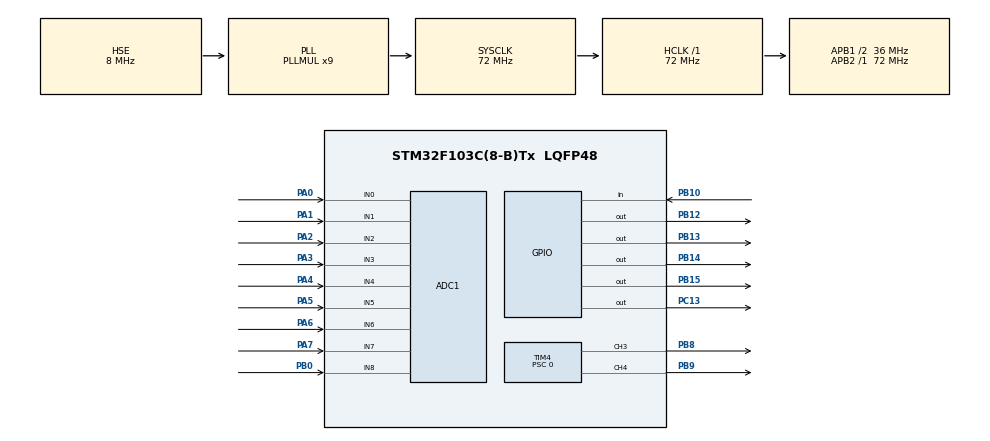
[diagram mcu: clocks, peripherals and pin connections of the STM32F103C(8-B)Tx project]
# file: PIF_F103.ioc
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ADC1.Channel-0\#ChannelRegularConversion=ADC_CHANNEL_0
ADC1.Channel-1\#ChannelRegularConversion=ADC_CHANNEL_1
ADC1.Channel-2\#ChannelRegularConversion=ADC_CHANNEL_2
ADC1.Channel-3\#ChannelRegularConversion=ADC_CHANNEL_3
ADC1.Channel-4\#ChannelRegularConversion=ADC_CHANNEL_4
ADC1.Channel-5\#ChannelRegularConversion=ADC_CHANNEL_5
ADC1.Channel-6\#ChannelRegularConversion=ADC_CHANNEL_6
ADC1.Channel-7\#ChannelRegularConversion=ADC_CHANNEL_7
ADC1.Channel-8\#ChannelRegularConversion=ADC_CHANNEL_8
ADC1.ContinuousConvMode=DISABLE
ADC1.ExternalTrigConv=ADC_EXTERNALTRIGCONV_T3_TRGO
ADC1.NbrOfConversion=9
ADC1.NbrOfConversionFlag=1
ADC1.Rank-0\#ChannelRegularConversion=1
ADC1.Rank-1\#ChannelRegularConversion=2
ADC1.Rank-2\#ChannelRegularConversion=3
ADC1.Rank-3\#ChannelRegularConversion=4
ADC1.Rank-4\#ChannelRegularConversion=5
ADC1.Rank-5\#ChannelRegularConversion=6
ADC1.Rank-6\#ChannelRegularConversion=7
ADC1.Rank-7\#ChannelRegularConversion=8
ADC1.Rank-8\#ChannelRegularConversion=9
ADC1.SamplingTime-0\#ChannelRegularConversion=ADC_SAMPLETIME_71CYCLES_5
ADC1.SamplingTime-1\#ChannelRegularConversion=ADC_SAMPLETIME_71CYCLES_5
ADC1.SamplingTime-2\#ChannelRegularConversion=ADC_SAMPLETIME_71CYCLES_5
ADC1.SamplingTime-3\#ChannelRegularConversion=ADC_SAMPLETIME_71CYCLES_5
ADC1.SamplingTime-4\#ChannelRegularConversion=ADC_SAMPLETIME_71CYCLES_5
ADC1.SamplingTime-5\#ChannelRegularConversion=ADC_SAMPLETIME_71CYCLES_5
ADC1.SamplingTime-6\#ChannelRegularConversion=ADC_SAMPLETIME_71CYCLES_5
ADC1.SamplingTime-7\#ChannelRegularConversion=ADC_SAMPLETIME_71CYCLES_5
ADC1.SamplingTime-8\#ChannelRegularConversion=ADC_SAMPLETIME_71CYCLES_5
ADC1.ScanConvMode=ADC_SCAN_ENABLE
ADC1.master=1
Dma.ADC1.0.Direction=DMA_PERIPH_TO_MEMORY
Dma.ADC1.0.Instance=DMA1_Channel1
Dma.ADC1.0.MemDataAlignment=DMA_MDATAALIGN_HALFWORD
Dma.ADC1.0.MemInc=DMA_MINC_ENABLE
Dma.ADC1.0.Mode=DMA_CIRCULAR
Dma.ADC1.0.PeriphDataAlignment=DMA_PDATAALIGN_HALFWORD
Dma.ADC1.0.PeriphInc=DMA_PINC_DISABLE
Dma.ADC1.0.Priority=DMA_PRIORITY_HIGH
Dma.Request0=ADC1
Mcu.Family=STM32F1
Mcu.Name=STM32F103C(8-B)Tx
Mcu.Package=LQFP48
NVIC.DMA1_Channel1_IRQn=true\:1\:0\:false\:false\:true\:true\:true\:true
NVIC.PriorityGroup=NVIC_PRIORITYGROUP_4
PA0-WKUP.Signal=ADCx_IN0
PA1.Signal=ADCx_IN1
PA13.Mode=Serial_Wire
PA13.Signal=SYS_JTMS-SWDIO
PA14.Mode=Serial_Wire
PA14.Signal=SYS_JTCK-SWCLK
PA2.Signal=ADCx_IN2
PA3.Signal=ADCx_IN3
PA4.Signal=ADCx_IN4
PA5.Signal=ADCx_IN5
PA6.Signal=ADCx_IN6
PA7.Signal=ADCx_IN7
PB0.Signal=ADCx_IN8
PB10.GPIO_PuPd=GPIO_PULLUP
PB10.Signal=GPIO_Input
PB12.Signal=GPIO_Output
PB13.Signal=GPIO_Output
PB14.Signal=GPIO_Output
PB15.Signal=GPIO_Output
PB8.Signal=S_TIM4_CH3
PB9.Signal=S_TIM4_CH4
PC13-TAMPER-RTC.Signal=GPIO_Output
PD0-OSC_IN.Mode=HSE-External-Oscillator
PD0-OSC_IN.Signal=RCC_OSC_IN
PD1-OSC_OUT.Mode=HSE-External-Oscillator
PD1-OSC_OUT.Signal=RCC_OSC_OUT
ProjectManager.HeapSize=0x200
ProjectManager.StackSize=0x400
ProjectManager.TargetToolchain=STM32CubeIDE
RCC.ADCPresc=RCC_ADCPCLK2_DIV6
RCC.APB1CLKDivider=RCC_HCLK_DIV2
RCC.APB1Freq_Value=36000000
RCC.APB1TimFreq_Value=72000000
RCC.APB2Freq_Value=72000000
RCC.HCLKFreq_Value=72000000
RCC.PLLMUL=RCC_PLL_MUL9
RCC.PLLSourceVirtual=RCC_PLLSOURCE_HSE
RCC.SYSCLKFreq_VALUE=72000000
RCC.SYSCLKSource=RCC_SYSCLKSOURCE_PLLCLK
SH.ADCx_IN0.0=ADC1_IN0,IN0
SH.ADCx_IN1.0=ADC1_IN1,IN1
SH.ADCx_IN2.0=ADC1_IN2,IN2
SH.ADCx_IN3.0=ADC1_IN3,IN3
SH.ADCx_IN4.0=ADC1_IN4,IN4
SH.ADCx_IN5.0=ADC1_IN5,IN5
SH.ADCx_IN6.0=ADC1_IN6,IN6
SH.ADCx_IN7.0=ADC1_IN7,IN7
SH.ADCx_IN8.0=ADC1_IN8,IN8
SH.S_TIM4_CH3.0=TIM4_CH3,PWM Generation3 CH3
SH.S_TIM4_CH4.0=TIM4_CH4,PWM Generation4 CH4
TIM3.Period=1999
TIM3.Prescaler=71
TIM3.TIM_MasterOutputTrigger=TIM_TRGO_UPDATE
TIM4.Channel-PWM\ Generation3\ CH3=TIM_CHANNEL_3
TIM4.Channel-PWM\ Generation4\ CH4=TIM_CHANNEL_4
TIM4.Period=7199
TIM4.Prescaler=0
VP_TIM3_VS_ClockSourceINT.Mode=Internal
VP_TIM4_VS_ClockSourceINT.Mode=Internal
board=custom

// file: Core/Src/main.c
/* Application entry for the Blue Pill. STM32CubeMX generates the HAL,
   startup, DMA interrupt handler and MSP code from PIF_F103.ioc. */
#include "main.h"
/* USER CODE BEGIN Includes */
#include "controller.h"
/* USER CODE END Includes */

ADC_HandleTypeDef hadc1;
DMA_HandleTypeDef hdma_adc1;
TIM_HandleTypeDef htim3, htim4;

static void require_ok(HAL_StatusTypeDef status) {
    if (status != HAL_OK) Error_Handler();
}

void SystemClock_Config(void) {
    RCC_OscInitTypeDef osc = {0};
    osc.OscillatorType = RCC_OSCILLATORTYPE_HSE;
    osc.HSEState = RCC_HSE_ON;
    osc.HSIState = RCC_HSI_ON;
    osc.PLL.PLLState = RCC_PLL_ON;
    osc.PLL.PLLSource = RCC_PLLSOURCE_HSE;
    osc.PLL.PLLMUL = RCC_PLL_MUL9;
    require_ok(HAL_RCC_OscConfig(&osc));

    RCC_ClkInitTypeDef clocks = {0};
    clocks.ClockType = RCC_CLOCKTYPE_SYSCLK | RCC_CLOCKTYPE_HCLK |
                       RCC_CLOCKTYPE_PCLK1 | RCC_CLOCKTYPE_PCLK2;
    clocks.SYSCLKSource = RCC_SYSCLKSOURCE_PLLCLK;
    clocks.AHBCLKDivider = RCC_SYSCLK_DIV1;
    clocks.APB1CLKDivider = RCC_HCLK_DIV2;
    clocks.APB2CLKDivider = RCC_HCLK_DIV1;
    require_ok(HAL_RCC_ClockConfig(&clocks, FLASH_LATENCY_2));

    RCC_PeriphCLKInitTypeDef adc_clock = {0};
    adc_clock.PeriphClockSelection = RCC_PERIPHCLK_ADC;
    adc_clock.AdcClockSelection = RCC_ADCPCLK2_DIV6;
    require_ok(HAL_RCCEx_PeriphCLKConfig(&adc_clock));
}

static void MX_GPIO_Init(void) {
    __HAL_RCC_GPIOA_CLK_ENABLE();
    __HAL_RCC_GPIOB_CLK_ENABLE();
    __HAL_RCC_GPIOC_CLK_ENABLE();
    const uint16_t direction = GPIO_PIN_12 | GPIO_PIN_13 | GPIO_PIN_14 | GPIO_PIN_15;
    HAL_GPIO_WritePin(GPIOB, direction, GPIO_PIN_RESET);
    HAL_GPIO_WritePin(GPIOC, GPIO_PIN_13, GPIO_PIN_SET);
    GPIO_InitTypeDef gpio = {0};
    gpio.Mode = GPIO_MODE_OUTPUT_PP;
    gpio.Speed = GPIO_SPEED_FREQ_LOW;
    gpio.Pin = direction;
    HAL_GPIO_Init(GPIOB, &gpio);
    gpio.Pin = GPIO_PIN_13;
    HAL_GPIO_Init(GPIOC, &gpio);
    gpio.Pin = GPIO_PIN_10;
    gpio.Mode = GPIO_MODE_INPUT;
    gpio.Pull = GPIO_PULLUP;
    HAL_GPIO_Init(GPIOB, &gpio);
}

static void MX_DMA_Init(void) {
    __HAL_RCC_DMA1_CLK_ENABLE();
    HAL_NVIC_SetPriority(DMA1_Channel1_IRQn, 1, 0);
    HAL_NVIC_EnableIRQ(DMA1_Channel1_IRQn);
}

static void MX_ADC1_Init(void) {
    static const uint32_t channels[] = {
        ADC_CHANNEL_0, ADC_CHANNEL_1, ADC_CHANNEL_2, ADC_CHANNEL_3, ADC_CHANNEL_4,
        ADC_CHANNEL_5, ADC_CHANNEL_6, ADC_CHANNEL_7, ADC_CHANNEL_8
    };
    hadc1.Instance = ADC1;
    hadc1.Init.ScanConvMode = ADC_SCAN_ENABLE;
    hadc1.Init.ContinuousConvMode = DISABLE;
    hadc1.Init.DiscontinuousConvMode = DISABLE;
    hadc1.Init.ExternalTrigConv = ADC_EXTERNALTRIGCONV_T3_TRGO;
    hadc1.Init.DataAlign = ADC_DATAALIGN_RIGHT;
    hadc1.Init.NbrOfConversion = 9;
    require_ok(HAL_ADC_Init(&hadc1));
    ADC_ChannelConfTypeDef channel = {0};
    channel.SamplingTime = ADC_SAMPLETIME_71CYCLES_5;
    for (unsigned i = 0; i < 9; ++i) {
        channel.Channel = channels[i];
        channel.Rank = i + 1;
        require_ok(HAL_ADC_ConfigChannel(&hadc1, &channel));
    }
}

static void MX_TIM3_Init(void) {
    __HAL_RCC_TIM3_CLK_ENABLE();
    htim3.Instance = TIM3;
    htim3.Init.Prescaler = 71;
    htim3.Init.CounterMode = TIM_COUNTERMODE_UP;
    htim3.Init.Period = 1999;
    htim3.Init.ClockDivision = TIM_CLOCKDIVISION_DIV1;
    require_ok(HAL_TIM_Base_Init(&htim3));
    TIM_MasterConfigTypeDef master = {0};
    master.MasterOutputTrigger = TIM_TRGO_UPDATE;
    master.MasterSlaveMode = TIM_MASTERSLAVEMODE_DISABLE;
    require_ok(HAL_TIMEx_MasterConfigSynchronization(&htim3, &master));
}

static void MX_TIM4_Init(void) {
    __HAL_RCC_TIM4_CLK_ENABLE();
    htim4.Instance = TIM4;
    htim4.Init.CounterMode = TIM_COUNTERMODE_UP;
    htim4.Init.Period = 7199;
    htim4.Init.ClockDivision = TIM_CLOCKDIVISION_DIV1;
    require_ok(HAL_TIM_PWM_Init(&htim4));
    TIM_OC_InitTypeDef oc = {0};
    oc.OCMode = TIM_OCMODE_PWM1;
    oc.OCPolarity = TIM_OCPOLARITY_HIGH;
    oc.OCFastMode = TIM_OCFAST_DISABLE;
    require_ok(HAL_TIM_PWM_ConfigChannel(&htim4, &oc, TIM_CHANNEL_3));
    require_ok(HAL_TIM_PWM_ConfigChannel(&htim4, &oc, TIM_CHANNEL_4));
    HAL_TIM_MspPostInit(&htim4);
}

int main(void) {
    HAL_Init();
    SystemClock_Config();
    MX_GPIO_Init();
    MX_DMA_Init();
    MX_ADC1_Init();
    MX_TIM3_Init();
    MX_TIM4_Init();
    /* USER CODE BEGIN 2 */
    Pif_Init(&hadc1, &htim3, &htim4);
    /* USER CODE END 2 */
    while (1) {
        /* USER CODE BEGIN 3 */
        Pif_Poll();
    }
    /* USER CODE END 3 */
}

void Error_Handler(void) {
    __disable_irq();
    if (htim4.Instance == TIM4) {
        __HAL_TIM_SET_COMPARE(&htim4, TIM_CHANNEL_3, 0);
        __HAL_TIM_SET_COMPARE(&htim4, TIM_CHANNEL_4, 0);
    }
    while (1) { }
}
